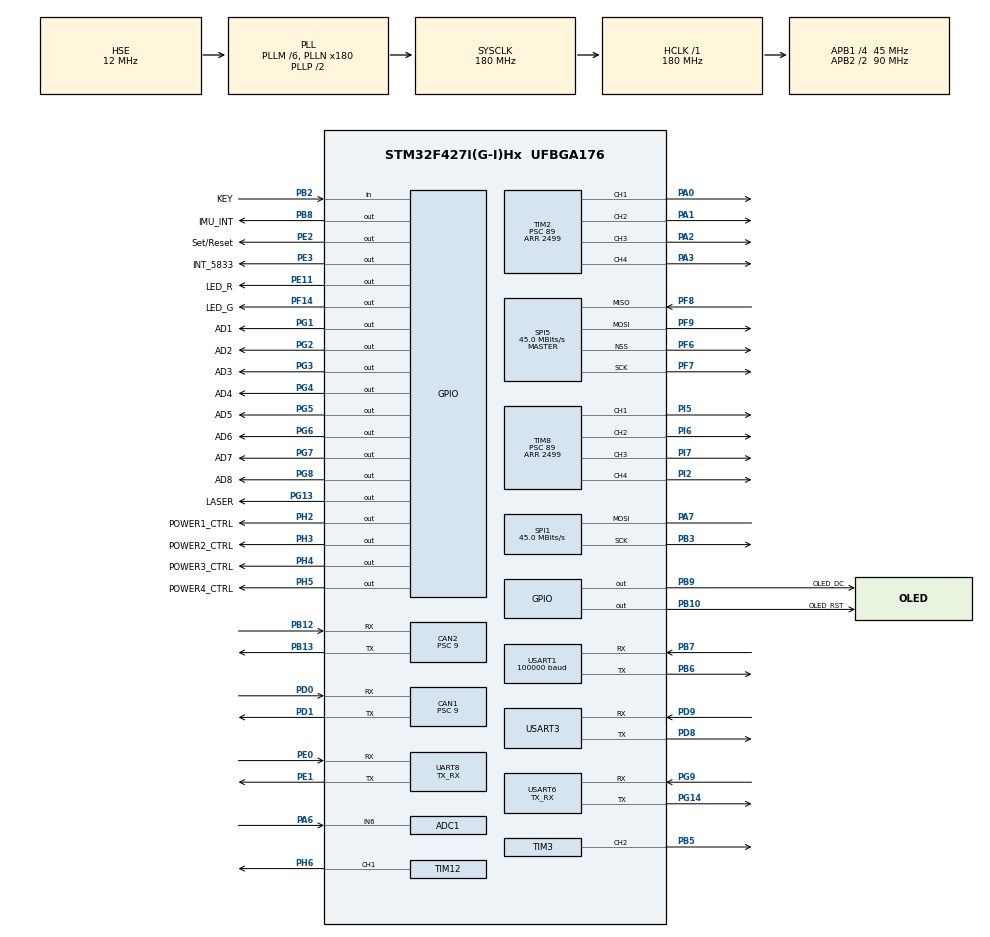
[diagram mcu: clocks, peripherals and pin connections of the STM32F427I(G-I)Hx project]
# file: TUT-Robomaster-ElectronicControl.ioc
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ADC1.Channel-2\#ChannelRegularConversion=ADC_CHANNEL_6
ADC1.ContinuousConvMode=ENABLE
ADC1.NbrOfConversionFlag=1
ADC1.Rank-2\#ChannelRegularConversion=1
ADC1.SamplingTime-2\#ChannelRegularConversion=ADC_SAMPLETIME_3CYCLES
ADC1.master=1
CAN1.ABOM=DISABLE
CAN1.BS1=CAN_BS1_3TQ
CAN1.CalculateBaudRate=1000000
CAN1.CalculateTimeBit=1000.00
CAN1.CalculateTimeQuantum=200.0
CAN1.NART=DISABLE
CAN1.Prescaler=9
CAN1.SJW=CAN_SJW_1TQ
CAN1.TXFP=DISABLE
CAN2.ABOM=DISABLE
CAN2.BS1=CAN_BS1_3TQ
CAN2.CalculateBaudRate=1000000
CAN2.CalculateTimeBit=1000.00
CAN2.CalculateTimeQuantum=200.0
CAN2.NART=DISABLE
CAN2.Prescaler=9
CAN2.SJW=CAN_SJW_1TQ
CAN2.TXFP=DISABLE
Dma.Request0=USART1_RX
Dma.Request1=UART8_RX
Dma.Request2=USART6_RX
Dma.Request3=USART3_RX
Dma.Request4=USART3_TX
Dma.Request5=SPI1_TX
Dma.Request6=SPI5_RX
Dma.Request7=SPI5_TX
Dma.Request8=USART6_TX
Dma.SPI1_TX.5.Direction=DMA_MEMORY_TO_PERIPH
Dma.SPI1_TX.5.FIFOMode=DMA_FIFOMODE_DISABLE
Dma.SPI1_TX.5.Instance=DMA2_Stream3
Dma.SPI1_TX.5.MemDataAlignment=DMA_MDATAALIGN_BYTE
Dma.SPI1_TX.5.MemInc=DMA_MINC_ENABLE
Dma.SPI1_TX.5.Mode=DMA_NORMAL
Dma.SPI1_TX.5.PeriphDataAlignment=DMA_PDATAALIGN_BYTE
Dma.SPI1_TX.5.PeriphInc=DMA_PINC_DISABLE
Dma.SPI1_TX.5.Priority=DMA_PRIORITY_LOW
Dma.SPI5_RX.6.Direction=DMA_PERIPH_TO_MEMORY
Dma.SPI5_RX.6.FIFOMode=DMA_FIFOMODE_DISABLE
Dma.SPI5_RX.6.Instance=DMA2_Stream5
Dma.SPI5_RX.6.MemDataAlignment=DMA_MDATAALIGN_BYTE
Dma.SPI5_RX.6.MemInc=DMA_MINC_ENABLE
Dma.SPI5_RX.6.Mode=DMA_NORMAL
Dma.SPI5_RX.6.PeriphDataAlignment=DMA_PDATAALIGN_BYTE
Dma.SPI5_RX.6.PeriphInc=DMA_PINC_DISABLE
Dma.SPI5_RX.6.Priority=DMA_PRIORITY_LOW
Dma.SPI5_TX.7.Direction=DMA_MEMORY_TO_PERIPH
Dma.SPI5_TX.7.FIFOMode=DMA_FIFOMODE_DISABLE
Dma.SPI5_TX.7.Instance=DMA2_Stream4
Dma.SPI5_TX.7.MemDataAlignment=DMA_MDATAALIGN_BYTE
Dma.SPI5_TX.7.MemInc=DMA_MINC_ENABLE
Dma.SPI5_TX.7.Mode=DMA_NORMAL
Dma.SPI5_TX.7.PeriphDataAlignment=DMA_PDATAALIGN_BYTE
Dma.SPI5_TX.7.PeriphInc=DMA_PINC_DISABLE
Dma.SPI5_TX.7.Priority=DMA_PRIORITY_LOW
Dma.UART8_RX.1.Direction=DMA_PERIPH_TO_MEMORY
Dma.UART8_RX.1.FIFOMode=DMA_FIFOMODE_DISABLE
Dma.UART8_RX.1.Instance=DMA1_Stream6
Dma.UART8_RX.1.MemDataAlignment=DMA_MDATAALIGN_BYTE
Dma.UART8_RX.1.MemInc=DMA_MINC_ENABLE
Dma.UART8_RX.1.Mode=DMA_CIRCULAR
Dma.UART8_RX.1.PeriphDataAlignment=DMA_PDATAALIGN_BYTE
Dma.UART8_RX.1.PeriphInc=DMA_PINC_DISABLE
Dma.UART8_RX.1.Priority=DMA_PRIORITY_LOW
Dma.USART1_RX.0.Direction=DMA_PERIPH_TO_MEMORY
Dma.USART1_RX.0.FIFOMode=DMA_FIFOMODE_DISABLE
Dma.USART1_RX.0.Instance=DMA2_Stream2
Dma.USART1_RX.0.MemDataAlignment=DMA_MDATAALIGN_BYTE
Dma.USART1_RX.0.MemInc=DMA_MINC_ENABLE
Dma.USART1_RX.0.Mode=DMA_CIRCULAR
Dma.USART1_RX.0.PeriphDataAlignment=DMA_PDATAALIGN_BYTE
Dma.USART1_RX.0.PeriphInc=DMA_PINC_DISABLE
Dma.USART1_RX.0.Priority=DMA_PRIORITY_LOW
Dma.USART3_RX.3.Direction=DMA_PERIPH_TO_MEMORY
Dma.USART3_RX.3.FIFOMode=DMA_FIFOMODE_DISABLE
Dma.USART3_RX.3.Instance=DMA1_Stream1
Dma.USART3_RX.3.MemDataAlignment=DMA_MDATAALIGN_BYTE
Dma.USART3_RX.3.MemInc=DMA_MINC_ENABLE
Dma.USART3_RX.3.Mode=DMA_CIRCULAR
Dma.USART3_RX.3.PeriphDataAlignment=DMA_PDATAALIGN_BYTE
Dma.USART3_RX.3.PeriphInc=DMA_PINC_DISABLE
Dma.USART3_RX.3.Priority=DMA_PRIORITY_LOW
Dma.USART3_TX.4.Direction=DMA_MEMORY_TO_PERIPH
Dma.USART3_TX.4.FIFOMode=DMA_FIFOMODE_DISABLE
Dma.USART3_TX.4.Instance=DMA1_Stream3
Dma.USART3_TX.4.MemDataAlignment=DMA_MDATAALIGN_BYTE
Dma.USART3_TX.4.MemInc=DMA_MINC_ENABLE
Dma.USART3_TX.4.Mode=DMA_NORMAL
Dma.USART3_TX.4.PeriphDataAlignment=DMA_PDATAALIGN_BYTE
Dma.USART3_TX.4.PeriphInc=DMA_PINC_DISABLE
Dma.USART3_TX.4.Priority=DMA_PRIORITY_LOW
Dma.USART6_RX.2.Direction=DMA_PERIPH_TO_MEMORY
Dma.USART6_RX.2.FIFOMode=DMA_FIFOMODE_DISABLE
Dma.USART6_RX.2.Instance=DMA2_Stream1
Dma.USART6_RX.2.MemDataAlignment=DMA_MDATAALIGN_BYTE
Dma.USART6_RX.2.MemInc=DMA_MINC_ENABLE
Dma.USART6_RX.2.Mode=DMA_CIRCULAR
Dma.USART6_RX.2.PeriphDataAlignment=DMA_PDATAALIGN_BYTE
Dma.USART6_RX.2.PeriphInc=DMA_PINC_DISABLE
Dma.USART6_RX.2.Priority=DMA_PRIORITY_LOW
Dma.USART6_TX.8.Direction=DMA_MEMORY_TO_PERIPH
Dma.USART6_TX.8.FIFOMode=DMA_FIFOMODE_DISABLE
Dma.USART6_TX.8.Instance=DMA2_Stream6
Dma.USART6_TX.8.MemDataAlignment=DMA_MDATAALIGN_BYTE
Dma.USART6_TX.8.MemInc=DMA_MINC_ENABLE
Dma.USART6_TX.8.Mode=DMA_NORMAL
Dma.USART6_TX.8.PeriphDataAlignment=DMA_PDATAALIGN_BYTE
Dma.USART6_TX.8.PeriphInc=DMA_PINC_DISABLE
Dma.USART6_TX.8.Priority=DMA_PRIORITY_LOW
FREERTOS.Tasks01=IdleTask,8,128,StartIdleTask,Default,NULL,Static,IdleTaskBuffer,IdleTaskControlBlock;chassisTask,48,1024,chassisTaskEntry,As external,NULL,Static,chassisTaskBuffer,chassisTaskControlBlock;gimbalTask,48,1024,gimbalTaskEntry,As external,NULL,Static,gimbalTaskBuffer,gimbalTaskControlBlock;shootTask,48,512,shootTaskEntry,As external,NULL,Static,shootTaskBuffer,shootTaskControlBlock;commonTask,48,512,commonTaskEntry,As external,NULL,Static,commonTaskBuffer,commonTaskControlBlock
FREERTOS.configENABLE_FPU=1
FREERTOS.configTOTAL_HEAP_SIZE=64000
FREERTOS.configUSE_PREEMPTION=0
Mcu.Family=STM32F4
Mcu.Name=STM32F427I(G-I)Hx
Mcu.Package=UFBGA176
NVIC.CAN1_RX0_IRQn=true\:5\:0\:true\:false\:true\:true\:true\:true
NVIC.CAN2_RX0_IRQn=true\:5\:0\:true\:false\:true\:false\:true\:true
NVIC.DMA1_Stream1_IRQn=true\:5\:0\:true\:false\:true\:false\:false\:true
NVIC.DMA1_Stream3_IRQn=true\:5\:0\:true\:false\:true\:false\:false\:true
NVIC.DMA1_Stream6_IRQn=true\:5\:0\:true\:false\:true\:false\:false\:true
NVIC.DMA2_Stream1_IRQn=true\:5\:0\:true\:false\:true\:false\:false\:true
NVIC.DMA2_Stream2_IRQn=true\:5\:0\:true\:false\:true\:false\:false\:true
NVIC.DMA2_Stream3_IRQn=true\:5\:0\:false\:false\:true\:true\:false\:true
NVIC.DMA2_Stream4_IRQn=true\:5\:0\:true\:false\:true\:true\:false\:true
NVIC.DMA2_Stream5_IRQn=true\:5\:0\:false\:false\:true\:true\:false\:true
NVIC.DMA2_Stream6_IRQn=true\:5\:0\:false\:false\:true\:true\:false\:true
NVIC.PriorityGroup=NVIC_PRIORITYGROUP_4
NVIC.SPI5_IRQn=true\:5\:0\:true\:false\:true\:false\:true\:true
NVIC.TIM6_DAC_IRQn=true\:0\:0\:false\:false\:true\:false\:false\:true
NVIC.TimeBase=TIM6_DAC_IRQn
NVIC.TimeBaseIP=TIM6
NVIC.UART8_IRQn=true\:5\:0\:false\:false\:true\:true\:true\:true
NVIC.USART1_IRQn=true\:5\:0\:true\:false\:true\:true\:true\:true
NVIC.USART3_IRQn=true\:5\:0\:true\:false\:true\:true\:true\:true
NVIC.USART6_IRQn=true\:5\:0\:false\:false\:true\:true\:true\:true
PA0/WKUP.Signal=S_TIM2_CH1_ETR
PA1.Signal=S_TIM2_CH2
PA13.Mode=Serial_Wire
PA13.Signal=SYS_JTMS-SWDIO
PA14.Mode=Serial_Wire
PA14.Signal=SYS_JTCK-SWCLK
PA2.Signal=S_TIM2_CH3
PA3.Signal=S_TIM2_CH4
PA6.Signal=ADCx_IN6
PA7.Mode=Simplex_Bidirectional_Master
PA7.Signal=SPI1_MOSI
PB10.GPIO_Label=OLED_RST
PB10.Signal=GPIO_Output
PB12.Mode=CAN_Activate
PB12.Signal=CAN2_RX
PB13.Mode=CAN_Activate
PB13.Signal=CAN2_TX
PB2/BOOT1.GPIO_Label=KEY
PB2/BOOT1.Signal=GPIO_Input
PB3.Mode=Simplex_Bidirectional_Master
PB3.Signal=SPI1_SCK
PB5.Signal=S_TIM3_CH2
PB6.Mode=Asynchronous
PB6.Signal=USART1_TX
PB7.Mode=Asynchronous
PB7.Signal=USART1_RX
PB8.GPIO_Label=IMU_INT
PB8.Signal=GPIO_Output
PB9.GPIO_Label=OLED_DC
PB9.Signal=GPIO_Output
PD0.Mode=CAN_Activate
PD0.Signal=CAN1_RX
PD1.Mode=CAN_Activate
PD1.Signal=CAN1_TX
PD8.Mode=Asynchronous
PD8.Signal=USART3_TX
PD9.Mode=Asynchronous
PD9.Signal=USART3_RX
PE0.Mode=Asynchronous
PE0.Signal=UART8_RX
PE1.Mode=Asynchronous
PE1.Signal=UART8_TX
PE11.GPIO_Label=LED_R
PE11.PinState=GPIO_PIN_SET
PE11.Signal=GPIO_Output
PE2.GPIO_Label=Set/Reset
PE2.Signal=GPIO_Output
PE3.GPIO_Label=INT_5833
PE3.Signal=GPIO_Output
PF14.GPIO_Label=LED_G
PF14.PinState=GPIO_PIN_SET
PF14.Signal=GPIO_Output
PF6.Mode=NSS_Signal_Hard_Output
PF6.Signal=SPI5_NSS
PF7.Mode=Full_Duplex_Master
PF7.Signal=SPI5_SCK
PF8.Mode=Full_Duplex_Master
PF8.Signal=SPI5_MISO
PF9.Mode=Full_Duplex_Master
PF9.Signal=SPI5_MOSI
PG1.GPIO_Label=AD1
PG1.PinState=GPIO_PIN_SET
PG1.Signal=GPIO_Output
PG13.GPIO_Label=LASER
PG13.Signal=GPIO_Output
PG14.Mode=Asynchronous
PG14.Signal=USART6_TX
PG2.GPIO_Label=AD2
PG2.PinState=GPIO_PIN_SET
PG2.Signal=GPIO_Output
PG3.GPIO_Label=AD3
PG3.PinState=GPIO_PIN_SET
PG3.Signal=GPIO_Output
PG4.GPIO_Label=AD4
PG4.PinState=GPIO_PIN_SET
PG4.Signal=GPIO_Output
PG5.GPIO_Label=AD5
PG5.GPIO_Speed=GPIO_SPEED_FREQ_LOW
PG5.PinState=GPIO_PIN_SET
PG5.Signal=GPIO_Output
PG6.GPIO_Label=AD6
PG6.GPIO_Speed=GPIO_SPEED_FREQ_LOW
PG6.PinState=GPIO_PIN_SET
PG6.Signal=GPIO_Output
PG7.GPIO_Label=AD7
PG7.GPIO_Speed=GPIO_SPEED_FREQ_LOW
PG7.PinState=GPIO_PIN_SET
PG7.Signal=GPIO_Output
PG8.GPIO_Label=AD8
PG8.GPIO_Speed=GPIO_SPEED_FREQ_LOW
PG8.PinState=GPIO_PIN_SET
PG8.Signal=GPIO_Output
PG9.Mode=Asynchronous
PG9.Signal=USART6_RX
PH0/OSC_IN.Mode=HSE-External-Oscillator
PH0/OSC_IN.Signal=RCC_OSC_IN
PH1/OSC_OUT.Mode=HSE-External-Oscillator
PH1/OSC_OUT.Signal=RCC_OSC_OUT
PH2.GPIO_Label=POWER1_CTRL
PH2.Signal=GPIO_Output
PH3.GPIO_Label=POWER2_CTRL
PH3.Signal=GPIO_Output
PH4.GPIO_Label=POWER3_CTRL
PH4.Signal=GPIO_Output
PH5.GPIO_Label=POWER4_CTRL
PH5.Signal=GPIO_Output
PH6.Signal=S_TIM12_CH1
PI2.Signal=S_TIM8_CH4
PI5.Signal=S_TIM8_CH1
PI6.Signal=S_TIM8_CH2
PI7.Signal=S_TIM8_CH3
ProjectManager.HeapSize=0x200
ProjectManager.StackSize=0x400
ProjectManager.TargetToolchain=MDK-ARM V5.27
RCC.48MHZClocksFreq_Value=45000000
RCC.AHBFreq_Value=180000000
RCC.APB1CLKDivider=RCC_HCLK_DIV4
RCC.APB1Freq_Value=45000000
RCC.APB1TimFreq_Value=90000000
RCC.APB2CLKDivider=RCC_HCLK_DIV2
RCC.APB2Freq_Value=90000000
RCC.APB2TimFreq_Value=180000000
RCC.CortexFreq_Value=180000000
RCC.DATA_CACHE_ENABLE=1
RCC.HCLKFreq_Value=180000000
RCC.HSE_VALUE=12000000
RCC.HSI_VALUE=16000000
RCC.LSE_VALUE=32768
RCC.PLLM=6
RCC.PLLN=180
RCC.PLLQ=8
RCC.PLLSourceVirtual=RCC_PLLSOURCE_HSE
RCC.SYSCLKFreq_VALUE=180000000
RCC.SYSCLKSource=RCC_SYSCLKSOURCE_PLLCLK
RCC.VCOOutputFreq_Value=360000000
SH.ADCx_IN6.0=ADC1_IN6,IN6
SH.S_TIM12_CH1.0=TIM12_CH1,PWM Generation1 CH1
SH.S_TIM2_CH1_ETR.0=TIM2_CH1,PWM Generation1 CH1
SH.S_TIM2_CH2.0=TIM2_CH2,PWM Generation2 CH2
SH.S_TIM2_CH3.0=TIM2_CH3,PWM Generation3 CH3
SH.S_TIM2_CH4.0=TIM2_CH4,PWM Generation4 CH4
SH.S_TIM3_CH2.0=TIM3_CH2,PWM Generation2 CH2
SH.S_TIM8_CH1.0=TIM8_CH1,PWM Generation1 CH1
SH.S_TIM8_CH2.0=TIM8_CH2,PWM Generation2 CH2
SH.S_TIM8_CH3.0=TIM8_CH3,PWM Generation3 CH3
SH.S_TIM8_CH4.0=TIM8_CH4,PWM Generation4 CH4
SPI1.CRCCalculation=SPI_CRCCALCULATION_DISABLE
SPI1.CalculateBaudRate=45.0 MBits/s
SPI1.Direction=SPI_DIRECTION_1LINE
SPI1.Mode=SPI_MODE_MASTER
SPI1.VirtualType=VM_MASTER
SPI5.CalculateBaudRate=45.0 MBits/s
SPI5.Direction=SPI_DIRECTION_2LINES
SPI5.Mode=SPI_MODE_MASTER
SPI5.VirtualNSS=VM_NSSHARD
SPI5.VirtualType=VM_MASTER
TIM12.Channel-PWM\ Generation1\ CH1=TIM_CHANNEL_1
TIM12.Period=999
TIM12.Prescaler=89
TIM2.Channel-PWM\ Generation1\ CH1=TIM_CHANNEL_1
TIM2.Channel-PWM\ Generation2\ CH2=TIM_CHANNEL_2
TIM2.Channel-PWM\ Generation3\ CH3=TIM_CHANNEL_3
TIM2.Channel-PWM\ Generation4\ CH4=TIM_CHANNEL_4
TIM2.Period=2499
TIM2.Prescaler=89
TIM3.Channel-PWM\ Generation2\ CH2=TIM_CHANNEL_2
TIM3.Period=2499
TIM3.Prescaler=89
TIM8.Channel-PWM\ Generation1\ CH1=TIM_CHANNEL_1
TIM8.Channel-PWM\ Generation2\ CH2=TIM_CHANNEL_2
TIM8.Channel-PWM\ Generation3\ CH3=TIM_CHANNEL_3
TIM8.Channel-PWM\ Generation4\ CH4=TIM_CHANNEL_4
TIM8.Period=2499
TIM8.Prescaler=89
UART8.Mode=MODE_TX_RX
UART8.VirtualMode=Asynchronous
USART1.BaudRate=100000
USART1.Mode=MODE_TX_RX
USART1.Parity=PARITY_EVEN
USART1.VirtualMode=VM_ASYNC
USART1.WordLength=WORDLENGTH_9B
USART3.VirtualMode=VM_ASYNC
USART6.Mode=MODE_TX_RX
USART6.VirtualMode=VM_ASYNC
VP_CRC_VS_CRC.Mode=CRC_Activate
VP_FREERTOS_VS_CMSIS_V2.Mode=CMSIS_V2
VP_SYS_VS_tim6.Mode=TIM6
board=custom

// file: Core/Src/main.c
/* USER CODE BEGIN Header */
/**
  ******************************************************************************
  * @file           : main.c
  * @brief          : Main program body
  ******************************************************************************
  * @attention
  *
  * <h2><center>&copy; Copyright (c) 2020 STMicroelectronics.
  * All rights reserved.</center></h2>
  *
  * This software component is licensed by ST under Ultimate Liberty license
  * SLA0044, the "License"; You may not use this file except in compliance with
  * the License. You may obtain a copy of the License at:
  *                             www.st.com/SLA0044
  *
  ******************************************************************************
  */
/* USER CODE END Header */
#include "main.h"
#include "cmsis_os.h"
#include "adc.h"
#include "can.h"
#include "crc.h"
#include "dma.h"
#include "spi.h"
#include "tim.h"
#include "usart.h"
#include "gpio.h"

void SystemClock_Config(void);
void MX_FREERTOS_Init(void);
/* USER CODE BEGIN PFP */
extern void System_Init(void);
/* USER CODE END PFP */

int main(void)
{

  /* MCU Configuration--------------------------------------------------------*/

  /* Reset of all peripherals, Initializes the Flash interface and the Systick. */
  HAL_Init();

  /* Configure the system clock */
  SystemClock_Config();

  /* Initialize all configured peripherals */
  MX_GPIO_Init();
  MX_DMA_Init();
  MX_ADC1_Init();
  MX_CAN1_Init();
  MX_SPI1_Init();
  MX_SPI5_Init();
  MX_TIM2_Init();
  MX_TIM3_Init();
  MX_TIM8_Init();
  MX_UART8_Init();
  MX_USART1_UART_Init();
  MX_CAN2_Init();
  MX_CRC_Init();
  MX_TIM12_Init();
  MX_USART6_UART_Init();
  MX_USART3_UART_Init();
  /* USER CODE BEGIN 2 */
	System_Init();
  /* USER CODE END 2 */

  /* Init scheduler */
  osKernelInitialize();  /* Call init function for freertos objects (in freertos.c) */
  MX_FREERTOS_Init();
  /* Start scheduler */
  osKernelStart();

  /* We should never get here as control is now taken by the scheduler */
  /* Infinite loop */
  while (1)
  {

  }
}

void SystemClock_Config(void)
{
  RCC_OscInitTypeDef RCC_OscInitStruct = {0};
  RCC_ClkInitTypeDef RCC_ClkInitStruct = {0};

  /** Configure the main internal regulator output voltage
  */
  __HAL_RCC_PWR_CLK_ENABLE();
  __HAL_PWR_VOLTAGESCALING_CONFIG(PWR_REGULATOR_VOLTAGE_SCALE1);
  /** Initializes the RCC Oscillators according to the specified parameters
  * in the RCC_OscInitTypeDef structure.
  */
  RCC_OscInitStruct.OscillatorType = RCC_OSCILLATORTYPE_HSE;
  RCC_OscInitStruct.HSEState = RCC_HSE_ON;
  RCC_OscInitStruct.PLL.PLLState = RCC_PLL_ON;
  RCC_OscInitStruct.PLL.PLLSource = RCC_PLLSOURCE_HSE;
  RCC_OscInitStruct.PLL.PLLM = 6;
  RCC_OscInitStruct.PLL.PLLN = 180;
  RCC_OscInitStruct.PLL.PLLP = RCC_PLLP_DIV2;
  RCC_OscInitStruct.PLL.PLLQ = 8;
  if (HAL_RCC_OscConfig(&RCC_OscInitStruct) != HAL_OK)
  {
    Error_Handler();
  }
  /** Activate the Over-Drive mode
  */
  if (HAL_PWREx_EnableOverDrive() != HAL_OK)
  {
    Error_Handler();
  }
  /** Initializes the CPU, AHB and APB buses clocks
  */
  RCC_ClkInitStruct.ClockType = RCC_CLOCKTYPE_HCLK|RCC_CLOCKTYPE_SYSCLK
                              |RCC_CLOCKTYPE_PCLK1|RCC_CLOCKTYPE_PCLK2;
  RCC_ClkInitStruct.SYSCLKSource = RCC_SYSCLKSOURCE_PLLCLK;
  RCC_ClkInitStruct.AHBCLKDivider = RCC_SYSCLK_DIV1;
  RCC_ClkInitStruct.APB1CLKDivider = RCC_HCLK_DIV4;
  RCC_ClkInitStruct.APB2CLKDivider = RCC_HCLK_DIV2;

  if (HAL_RCC_ClockConfig(&RCC_ClkInitStruct, FLASH_LATENCY_5) != HAL_OK)
  {
    Error_Handler();
  }
}

 /**
  * @brief  Period elapsed callback in non blocking mode
  * @note   This function is called  when TIM6 interrupt took place, inside
  * HAL_TIM_IRQHandler(). It makes a direct call to HAL_IncTick() to increment
  * a global variable "uwTick" used as application time base.
  * @param  htim : TIM handle
  * @retval None
  */
void HAL_TIM_PeriodElapsedCallback(TIM_HandleTypeDef *htim)
{
  if (htim->Instance == TIM6) {
    HAL_IncTick();
  }
}

void Error_Handler(void)
{
  __disable_irq();
  while (1)
  {
  }
}

/************************ (C) COPYRIGHT STMicroelectronics *****END OF FILE****/

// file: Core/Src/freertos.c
/* USER CODE BEGIN Header */
/**
  ******************************************************************************
  * File Name          : freertos.c
  * Description        : Code for freertos applications
  ******************************************************************************
  * @attention
  *
  * <h2><center>&copy; Copyright (c) 2020 STMicroelectronics.
  * All rights reserved.</center></h2>
  *
  * This software component is licensed by ST under Ultimate Liberty license
  * SLA0044, the "License"; You may not use this file except in compliance with
  * the License. You may obtain a copy of the License at:
  *                             www.st.com/SLA0044
  *
  ******************************************************************************
  */
/* USER CODE END Header */

#include "FreeRTOS.h"
#include "task.h"
#include "main.h"
#include "cmsis_os.h"

typedef StaticTask_t osStaticThreadDef_t;

/* Definitions for IdleTask */
osThreadId_t IdleTaskHandle;
uint32_t IdleTaskBuffer[ 128 ];
osStaticThreadDef_t IdleTaskControlBlock;
const osThreadAttr_t IdleTask_attributes = {
  .name = "IdleTask",
  .stack_mem = &IdleTaskBuffer[0],
  .stack_size = sizeof(IdleTaskBuffer),
  .cb_mem = &IdleTaskControlBlock,
  .cb_size = sizeof(IdleTaskControlBlock),
  .priority = (osPriority_t) osPriorityLow,
};
/* Definitions for chassisTask */
osThreadId_t chassisTaskHandle;
uint32_t chassisTaskBuffer[ 1024 ];
osStaticThreadDef_t chassisTaskControlBlock;
const osThreadAttr_t chassisTask_attributes = {
  .name = "chassisTask",
  .stack_mem = &chassisTaskBuffer[0],
  .stack_size = sizeof(chassisTaskBuffer),
  .cb_mem = &chassisTaskControlBlock,
  .cb_size = sizeof(chassisTaskControlBlock),
  .priority = (osPriority_t) osPriorityRealtime,
};
/* Definitions for gimbalTask */
osThreadId_t gimbalTaskHandle;
uint32_t gimbalTaskBuffer[ 1024 ];
osStaticThreadDef_t gimbalTaskControlBlock;
const osThreadAttr_t gimbalTask_attributes = {
  .name = "gimbalTask",
  .stack_mem = &gimbalTaskBuffer[0],
  .stack_size = sizeof(gimbalTaskBuffer),
  .cb_mem = &gimbalTaskControlBlock,
  .cb_size = sizeof(gimbalTaskControlBlock),
  .priority = (osPriority_t) osPriorityRealtime,
};
/* Definitions for shootTask */
osThreadId_t shootTaskHandle;
uint32_t shootTaskBuffer[ 512 ];
osStaticThreadDef_t shootTaskControlBlock;
const osThreadAttr_t shootTask_attributes = {
  .name = "shootTask",
  .stack_mem = &shootTaskBuffer[0],
  .stack_size = sizeof(shootTaskBuffer),
  .cb_mem = &shootTaskControlBlock,
  .cb_size = sizeof(shootTaskControlBlock),
  .priority = (osPriority_t) osPriorityRealtime,
};
/* Definitions for commonTask */
osThreadId_t commonTaskHandle;
uint32_t commonTaskBuffer[ 512 ];
osStaticThreadDef_t commonTaskControlBlock;
const osThreadAttr_t commonTask_attributes = {
  .name = "commonTask",
  .stack_mem = &commonTaskBuffer[0],
  .stack_size = sizeof(commonTaskBuffer),
  .cb_mem = &commonTaskControlBlock,
  .cb_size = sizeof(commonTaskControlBlock),
  .priority = (osPriority_t) osPriorityRealtime,
};

void StartIdleTask(void *argument);
extern void chassisTaskEntry(void *argument);
extern void gimbalTaskEntry(void *argument);
extern void shootTaskEntry(void *argument);
extern void commonTaskEntry(void *argument);

void MX_FREERTOS_Init(void); /* (MISRA C 2004 rule 8.1) */

void MX_FREERTOS_Init(void) {

  /* Create the thread(s) */
  /* creation of IdleTask */
  IdleTaskHandle = osThreadNew(StartIdleTask, NULL, &IdleTask_attributes);

  /* creation of chassisTask */
  chassisTaskHandle = osThreadNew(chassisTaskEntry, NULL, &chassisTask_attributes);

  /* creation of gimbalTask */
  gimbalTaskHandle = osThreadNew(gimbalTaskEntry, NULL, &gimbalTask_attributes);

  /* creation of shootTask */
  shootTaskHandle = osThreadNew(shootTaskEntry, NULL, &shootTask_attributes);

  /* creation of commonTask */
  commonTaskHandle = osThreadNew(commonTaskEntry, NULL, &commonTask_attributes);

}

void StartIdleTask(void *argument)
{
  for(;;)
  {
    osDelay(1);
  }
}

/************************ (C) COPYRIGHT STMicroelectronics *****END OF FILE****/
